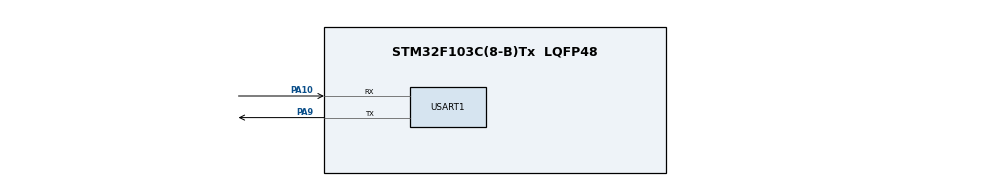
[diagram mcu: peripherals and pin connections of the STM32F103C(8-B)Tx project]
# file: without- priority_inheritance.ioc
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FREERTOS.BinarySemaphores01=myBinarySem1,Dynamic,NULL,Available
FREERTOS.Tasks01=defaultTask,0,128,StartDefaultTask,Default,NULL,Dynamic,NULL,NULL;myTask01,-2,128,myTask_01,Default,NULL,Dynamic,NULL,NULL;myTask02,0,128,StartTask_02,Default,NULL,Dynamic,NULL,NULL;myTask03,2,128,StartTask_34,Default,NULL,Dynamic,NULL,NULL
Mcu.Family=STM32F1
Mcu.Name=STM32F103C(8-B)Tx
Mcu.Package=LQFP48
NVIC.PriorityGroup=NVIC_PRIORITYGROUP_4
NVIC.TIM1_UP_IRQn=true\:15\:0\:false\:false\:true\:false\:false\:true\:true
NVIC.TimeBase=TIM1_UP_IRQn
NVIC.TimeBaseIP=TIM1
PA10.Mode=Asynchronous
PA10.Signal=USART1_RX
PA9.Mode=Asynchronous
PA9.Signal=USART1_TX
PD0-OSC_IN.Mode=HSE-External-Oscillator
PD0-OSC_IN.Signal=RCC_OSC_IN
PD1-OSC_OUT.Mode=HSE-External-Oscillator
PD1-OSC_OUT.Signal=RCC_OSC_OUT
ProjectManager.HeapSize=0x200
ProjectManager.StackSize=0x400
ProjectManager.TargetToolchain=STM32CubeIDE
RCC.APB1Freq_Value=8000000
RCC.APB2Freq_Value=8000000
USART1.VirtualMode=VM_ASYNC
VP_FREERTOS_VS_CMSIS_V1.Mode=CMSIS_V1
VP_SYS_VS_ND.Mode=No_Debug
VP_SYS_VS_tim1.Mode=TIM1
board=custom

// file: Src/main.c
/* USER CODE BEGIN Header */
/**
  ******************************************************************************
  * @file           : main.c
  * @brief          : Main program body
  ******************************************************************************
  * @attention
  *
  * Copyright (c) 2026 STMicroelectronics.
  * All rights reserved.
  *
  * This software is licensed under terms that can be found in the LICENSE file
  * in the root directory of this software component.
  * If no LICENSE file comes with this software, it is provided AS-IS.
  *
  ******************************************************************************
  */
/* USER CODE END Header */
#include "main.h"
#include "cmsis_os.h"

UART_HandleTypeDef huart1;

osThreadId defaultTaskHandle;
osThreadId myTask01Handle;
osThreadId myTask02Handle;
osThreadId myTask03Handle;
osSemaphoreId myBinarySem1Handle;

void SystemClock_Config(void);
static void MX_GPIO_Init(void);
static void MX_USART1_UART_Init(void);
void StartDefaultTask(void const * argument);
void myTask_01(void const * argument);
void StartTask_02(void const * argument);
void StartTask_34(void const * argument);

int main(void)
{

  /* MCU Configuration--------------------------------------------------------*/

  /* Reset of all peripherals, Initializes the Flash interface and the Systick. */
  HAL_Init();

  /* Configure the system clock */
  SystemClock_Config();

  /* Initialize all configured peripherals */
  MX_GPIO_Init();
  MX_USART1_UART_Init();

  /* Create the semaphores(s) */
  /* definition and creation of myBinarySem1 */
  osSemaphoreDef(myBinarySem1);
  myBinarySem1Handle = osSemaphoreCreate(osSemaphore(myBinarySem1), 1);

  /* Create the thread(s) */
  /* definition and creation of defaultTask */
  osThreadDef(defaultTask, StartDefaultTask, osPriorityNormal, 0, 128);
  defaultTaskHandle = osThreadCreate(osThread(defaultTask), NULL);

  /* definition and creation of myTask01 */
  osThreadDef(myTask01, myTask_01, osPriorityLow, 0, 128);
  myTask01Handle = osThreadCreate(osThread(myTask01), NULL);

  /* definition and creation of myTask02 */
  osThreadDef(myTask02, StartTask_02, osPriorityNormal, 0, 128);
  myTask02Handle = osThreadCreate(osThread(myTask02), NULL);

  /* definition and creation of myTask03 */
  osThreadDef(myTask03, StartTask_34, osPriorityHigh, 0, 128);
  myTask03Handle = osThreadCreate(osThread(myTask03), NULL);

  /* Start scheduler */
  osKernelStart();

  /* We should never get here as control is now taken by the scheduler */

  /* Infinite loop */
  while (1)
  {

  }
}

void SystemClock_Config(void)
{
  RCC_OscInitTypeDef RCC_OscInitStruct = {0};
  RCC_ClkInitTypeDef RCC_ClkInitStruct = {0};

  /** Initializes the RCC Oscillators according to the specified parameters
  * in the RCC_OscInitTypeDef structure.
  */
  RCC_OscInitStruct.OscillatorType = RCC_OSCILLATORTYPE_HSI;
  RCC_OscInitStruct.HSIState = RCC_HSI_ON;
  RCC_OscInitStruct.HSICalibrationValue = RCC_HSICALIBRATION_DEFAULT;
  RCC_OscInitStruct.PLL.PLLState = RCC_PLL_NONE;
  if (HAL_RCC_OscConfig(&RCC_OscInitStruct) != HAL_OK)
  {
    Error_Handler();
  }

  /** Initializes the CPU, AHB and APB buses clocks
  */
  RCC_ClkInitStruct.ClockType = RCC_CLOCKTYPE_HCLK|RCC_CLOCKTYPE_SYSCLK
                              |RCC_CLOCKTYPE_PCLK1|RCC_CLOCKTYPE_PCLK2;
  RCC_ClkInitStruct.SYSCLKSource = RCC_SYSCLKSOURCE_HSI;
  RCC_ClkInitStruct.AHBCLKDivider = RCC_SYSCLK_DIV1;
  RCC_ClkInitStruct.APB1CLKDivider = RCC_HCLK_DIV1;
  RCC_ClkInitStruct.APB2CLKDivider = RCC_HCLK_DIV1;

  if (HAL_RCC_ClockConfig(&RCC_ClkInitStruct, FLASH_LATENCY_0) != HAL_OK)
  {
    Error_Handler();
  }
}

static void MX_USART1_UART_Init(void)
{

  huart1.Instance = USART1;
  huart1.Init.BaudRate = 115200;
  huart1.Init.WordLength = UART_WORDLENGTH_8B;
  huart1.Init.StopBits = UART_STOPBITS_1;
  huart1.Init.Parity = UART_PARITY_NONE;
  huart1.Init.Mode = UART_MODE_TX_RX;
  huart1.Init.HwFlowCtl = UART_HWCONTROL_NONE;
  huart1.Init.OverSampling = UART_OVERSAMPLING_16;
  if (HAL_UART_Init(&huart1) != HAL_OK)
  {
    Error_Handler();
  }

}

static void MX_GPIO_Init(void)
{

  /* GPIO Ports Clock Enable */
  __HAL_RCC_GPIOD_CLK_ENABLE();
  __HAL_RCC_GPIOA_CLK_ENABLE();

}

void StartDefaultTask(void const * argument)
{
  for(;;)
  {
    osDelay(1);
  }
}

void myTask_01(void const * argument)
{
  /* USER CODE BEGIN myTask_01 */
  /* Infinite loop */
	  char *acq_msg = "Low Task : Semaphore acquired — holding for 3s...\r\n";
	  char *rel_msg = "Low Task : Semaphore released!\r\n";

	  for(;;)
	  {
	    osSemaphoreAcquire(myMutex01Handle , osWaitForever);
	    HAL_UART_Transmit(&huart1, (uint8_t*)acq_msg, strlen(acq_msg), 100);

	    HAL_Delay(3000);

	    HAL_UART_Transmit(&huart1, (uint8_t*)rel_msg, strlen(rel_msg), 100);
	    osSemaphoreRelease(myMutex01Handle );

	    osDelay(1000);
	  }
  /* USER CODE END myTask_01 */
}

void StartTask_02(void const * argument)
{
  /* USER CODE BEGIN StartTask_02 */
  /* Infinite loop */
	osDelay(500);

	  char *start_msg = "Med  Task : Hogging CPU...\r\n";
	  char *done_msg  = "Med  Task : Done hogging.\r\n";

	  for(;;)
	  {
	    HAL_UART_Transmit(&huart1, (uint8_t*)start_msg, strlen(start_msg), 100);

	    for(volatile uint32_t i = 0; i < 30000000; i++) { __asm("NOP"); }

	    HAL_UART_Transmit(&huart1, (uint8_t*)done_msg, strlen(done_msg), 100);
	    osDelay(5000);
	  }
  /* USER CODE END StartTask_02 */
}

void StartTask_34(void const * argument)
{
  /* USER CODE BEGIN StartTask_34 */
  /* Infinite loop */
	  osDelay(1000);   // Let Task1 acquire the semaphore first

	  char *wait_msg    = "High Task : Waiting for semaphore...\r\n";
	  char *success_msg = "High Task : Got semaphore — running!\r\n";

	  for(;;)
	  {
	    HAL_UART_Transmit(&huart1, (uint8_t*)wait_msg, strlen(wait_msg), 100);

	    osSemaphoreAcquire(myMutex01Handle , osWaitForever);  // BLOCKED here!

	    HAL_UART_Transmit(&huart1, (uint8_t*)success_msg, strlen(success_msg), 100);
	    osSemaphoreRelease(myMutex01Handle );

	    osDelay(500);
	  }
  /* USER CODE END StartTask_34 */
}

void HAL_TIM_PeriodElapsedCallback(TIM_HandleTypeDef *htim)
{
  if (htim->Instance == TIM1)
  {
    HAL_IncTick();
  }
}

void Error_Handler(void)
{
  __disable_irq();
  while (1)
  {
  }
}
